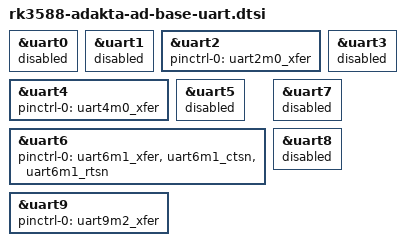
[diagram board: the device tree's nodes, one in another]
// SPDX-License-Identifier: (GPL-2.0+ OR MIT)
/*
 * Copyright (c) 2024 Adakta, Ltd.
 *
 */

&uart0 {
	status = "disabled";
};

&uart1 {
	status = "disabled";
};

&uart2 {
	pinctrl-names = "default";
	pinctrl-0 = <&uart2m0_xfer>;
	status = "okay";
};

&uart3 {
	status = "disabled";
};

&uart4 {
	pinctrl-names = "default";
	pinctrl-0 = <&uart4m0_xfer>;
	status = "okay";
};

&uart5 {
	status = "disabled";
};

&uart6 {
	pinctrl-names = "default";
	pinctrl-0 = <&uart6m1_xfer &uart6m1_ctsn &uart6m1_rtsn>;
	status = "okay";
};

&uart7 {
	status = "disabled";
};

&uart8 {
	status = "disabled";
};

&uart9 {
	pinctrl-names = "default";
	pinctrl-0 = <&uart9m2_xfer>;
	status = "okay";
};
